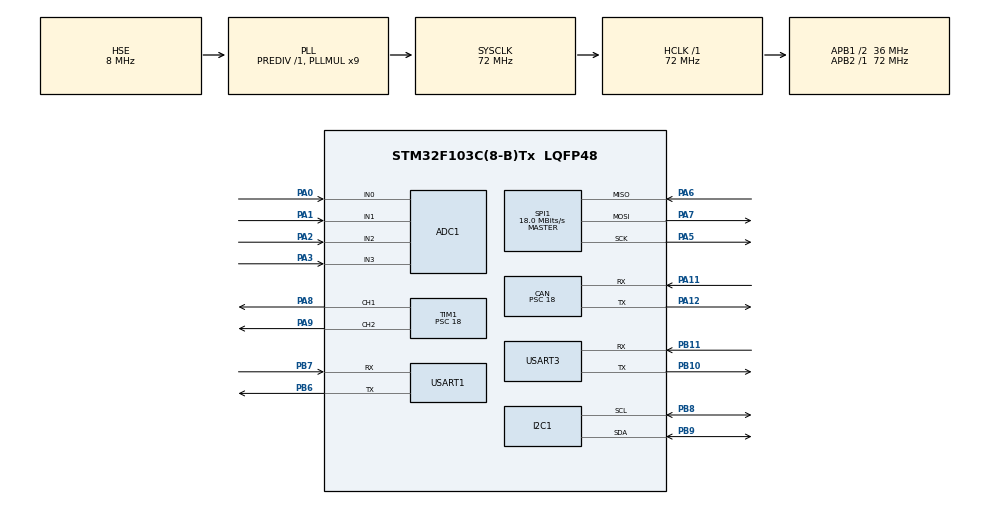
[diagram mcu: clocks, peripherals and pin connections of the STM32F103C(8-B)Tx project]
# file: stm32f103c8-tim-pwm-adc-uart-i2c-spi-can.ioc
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ADC1.Channel-0\#ChannelRegularConversion=ADC_CHANNEL_0
ADC1.Channel-1\#ChannelRegularConversion=ADC_CHANNEL_1
ADC1.Channel-2\#ChannelRegularConversion=ADC_CHANNEL_2
ADC1.Channel-3\#ChannelRegularConversion=ADC_CHANNEL_3
ADC1.ContinuousConvMode=ENABLE
ADC1.NbrOfConversion=4
ADC1.NbrOfConversionFlag=1
ADC1.Rank-0\#ChannelRegularConversion=1
ADC1.Rank-1\#ChannelRegularConversion=2
ADC1.Rank-2\#ChannelRegularConversion=3
ADC1.Rank-3\#ChannelRegularConversion=4
ADC1.SamplingTime-0\#ChannelRegularConversion=ADC_SAMPLETIME_28CYCLES_5
ADC1.SamplingTime-1\#ChannelRegularConversion=ADC_SAMPLETIME_28CYCLES_5
ADC1.SamplingTime-2\#ChannelRegularConversion=ADC_SAMPLETIME_28CYCLES_5
ADC1.SamplingTime-3\#ChannelRegularConversion=ADC_SAMPLETIME_28CYCLES_5
ADC1.master=1
CAN.BS1=CAN_BS1_3TQ
CAN.BS2=CAN_BS2_4TQ
CAN.CalculateBaudRate=250000
CAN.CalculateTimeBit=4000.00
CAN.CalculateTimeQuantum=500.0
CAN.Prescaler=18
Dma.ADC1.6.Direction=DMA_PERIPH_TO_MEMORY
Dma.ADC1.6.Instance=DMA1_Channel1
Dma.ADC1.6.MemDataAlignment=DMA_MDATAALIGN_HALFWORD
Dma.ADC1.6.MemInc=DMA_MINC_ENABLE
Dma.ADC1.6.Mode=DMA_CIRCULAR
Dma.ADC1.6.PeriphDataAlignment=DMA_PDATAALIGN_HALFWORD
Dma.ADC1.6.PeriphInc=DMA_PINC_DISABLE
Dma.ADC1.6.Priority=DMA_PRIORITY_HIGH
Dma.I2C1_RX.2.Direction=DMA_PERIPH_TO_MEMORY
Dma.I2C1_RX.2.Instance=DMA1_Channel7
Dma.I2C1_RX.2.MemDataAlignment=DMA_MDATAALIGN_BYTE
Dma.I2C1_RX.2.MemInc=DMA_MINC_ENABLE
Dma.I2C1_RX.2.Mode=DMA_NORMAL
Dma.I2C1_RX.2.PeriphDataAlignment=DMA_PDATAALIGN_BYTE
Dma.I2C1_RX.2.PeriphInc=DMA_PINC_DISABLE
Dma.I2C1_RX.2.Priority=DMA_PRIORITY_HIGH
Dma.I2C1_TX.3.Direction=DMA_MEMORY_TO_PERIPH
Dma.I2C1_TX.3.Instance=DMA1_Channel6
Dma.I2C1_TX.3.MemDataAlignment=DMA_MDATAALIGN_BYTE
Dma.I2C1_TX.3.MemInc=DMA_MINC_ENABLE
Dma.I2C1_TX.3.Mode=DMA_NORMAL
Dma.I2C1_TX.3.PeriphDataAlignment=DMA_PDATAALIGN_BYTE
Dma.I2C1_TX.3.PeriphInc=DMA_PINC_DISABLE
Dma.I2C1_TX.3.Priority=DMA_PRIORITY_HIGH
Dma.Request0=USART1_RX
Dma.Request1=USART1_TX
Dma.Request2=I2C1_RX
Dma.Request3=I2C1_TX
Dma.Request4=SPI1_RX
Dma.Request5=SPI1_TX
Dma.Request6=ADC1
Dma.SPI1_RX.4.Direction=DMA_PERIPH_TO_MEMORY
Dma.SPI1_RX.4.Instance=DMA1_Channel2
Dma.SPI1_RX.4.MemDataAlignment=DMA_MDATAALIGN_BYTE
Dma.SPI1_RX.4.MemInc=DMA_MINC_ENABLE
Dma.SPI1_RX.4.Mode=DMA_NORMAL
Dma.SPI1_RX.4.PeriphDataAlignment=DMA_PDATAALIGN_BYTE
Dma.SPI1_RX.4.PeriphInc=DMA_PINC_DISABLE
Dma.SPI1_RX.4.Priority=DMA_PRIORITY_HIGH
Dma.SPI1_TX.5.Direction=DMA_MEMORY_TO_PERIPH
Dma.SPI1_TX.5.Instance=DMA1_Channel3
Dma.SPI1_TX.5.MemDataAlignment=DMA_MDATAALIGN_BYTE
Dma.SPI1_TX.5.MemInc=DMA_MINC_ENABLE
Dma.SPI1_TX.5.Mode=DMA_NORMAL
Dma.SPI1_TX.5.PeriphDataAlignment=DMA_PDATAALIGN_BYTE
Dma.SPI1_TX.5.PeriphInc=DMA_PINC_DISABLE
Dma.SPI1_TX.5.Priority=DMA_PRIORITY_HIGH
Dma.USART1_RX.0.Direction=DMA_PERIPH_TO_MEMORY
Dma.USART1_RX.0.Instance=DMA1_Channel5
Dma.USART1_RX.0.MemDataAlignment=DMA_MDATAALIGN_BYTE
Dma.USART1_RX.0.MemInc=DMA_MINC_ENABLE
Dma.USART1_RX.0.Mode=DMA_CIRCULAR
Dma.USART1_RX.0.PeriphDataAlignment=DMA_PDATAALIGN_BYTE
Dma.USART1_RX.0.PeriphInc=DMA_PINC_DISABLE
Dma.USART1_RX.0.Priority=DMA_PRIORITY_HIGH
Dma.USART1_TX.1.Direction=DMA_MEMORY_TO_PERIPH
Dma.USART1_TX.1.Instance=DMA1_Channel4
Dma.USART1_TX.1.MemDataAlignment=DMA_MDATAALIGN_BYTE
Dma.USART1_TX.1.MemInc=DMA_MINC_ENABLE
Dma.USART1_TX.1.Mode=DMA_NORMAL
Dma.USART1_TX.1.PeriphDataAlignment=DMA_PDATAALIGN_BYTE
Dma.USART1_TX.1.PeriphInc=DMA_PINC_DISABLE
Dma.USART1_TX.1.Priority=DMA_PRIORITY_HIGH
FREERTOS.Tasks01=defaultTask,24,128,StartDefaultTask,Default,NULL,Dynamic,NULL,NULL
FREERTOS.Timers01=myTimer01,Callback01,osTimerPeriodic,Default,NULL,Dynamic,NULL
I2C1.I2C_Mode=I2C_Fast
IWDG.Prescaler=IWDG_PRESCALER_64
Mcu.Family=STM32F1
Mcu.Name=STM32F103C(8-B)Tx
Mcu.Package=LQFP48
NVIC.ADC1_2_IRQn=true\:5\:0\:false\:false\:true\:true\:true\:true
NVIC.CAN1_SCE_IRQn=true\:5\:0\:false\:false\:true\:true\:true\:true
NVIC.DMA1_Channel1_IRQn=true\:5\:0\:false\:false\:true\:true\:false\:true
NVIC.DMA1_Channel2_IRQn=true\:5\:0\:false\:false\:true\:true\:false\:true
NVIC.DMA1_Channel3_IRQn=true\:5\:0\:false\:false\:true\:true\:false\:true
NVIC.DMA1_Channel4_IRQn=true\:5\:0\:false\:false\:true\:true\:false\:true
NVIC.DMA1_Channel5_IRQn=true\:5\:0\:false\:false\:true\:true\:false\:true
NVIC.DMA1_Channel6_IRQn=true\:5\:0\:false\:false\:true\:true\:false\:true
NVIC.DMA1_Channel7_IRQn=true\:5\:0\:false\:false\:true\:true\:false\:true
NVIC.I2C1_ER_IRQn=true\:5\:0\:false\:false\:true\:true\:true\:true
NVIC.I2C1_EV_IRQn=true\:5\:0\:false\:false\:true\:true\:true\:true
NVIC.PriorityGroup=NVIC_PRIORITYGROUP_4
NVIC.SPI1_IRQn=true\:5\:0\:false\:false\:true\:true\:true\:true
NVIC.TIM1_BRK_IRQn=true\:5\:0\:false\:false\:true\:true\:true\:true
NVIC.TIM1_CC_IRQn=true\:5\:0\:false\:false\:true\:true\:true\:true
NVIC.TIM1_TRG_COM_IRQn=true\:5\:0\:false\:false\:true\:true\:true\:true
NVIC.TIM1_UP_IRQn=true\:5\:0\:false\:false\:true\:true\:true\:true
NVIC.TIM4_IRQn=true\:0\:0\:false\:false\:true\:false\:false\:true
NVIC.TimeBase=TIM4_IRQn
NVIC.TimeBaseIP=TIM4
NVIC.USART1_IRQn=true\:5\:0\:false\:false\:true\:true\:true\:true
NVIC.USART3_IRQn=true\:5\:0\:false\:false\:true\:true\:true\:true
NVIC.USB_HP_CAN1_TX_IRQn=true\:5\:0\:false\:false\:true\:true\:true\:true
NVIC.USB_LP_CAN1_RX0_IRQn=true\:5\:0\:false\:false\:true\:true\:true\:true
PA0-WKUP.Signal=ADCx_IN0
PA1.Signal=ADCx_IN1
PA11.Mode=CAN_Activate
PA11.Signal=CAN_RX
PA12.Mode=CAN_Activate
PA12.Signal=CAN_TX
PA13.Mode=Serial_Wire
PA13.Signal=SYS_JTMS-SWDIO
PA14.Mode=Serial_Wire
PA14.Signal=SYS_JTCK-SWCLK
PA2.Signal=ADCx_IN2
PA3.Signal=ADCx_IN3
PA5.Mode=Full_Duplex_Master
PA5.Signal=SPI1_SCK
PA6.Mode=Full_Duplex_Master
PA6.Signal=SPI1_MISO
PA7.Mode=Full_Duplex_Master
PA7.Signal=SPI1_MOSI
PA8.Signal=S_TIM1_CH1
PA9.Signal=S_TIM1_CH2
PB10.Mode=Asynchronous
PB10.Signal=USART3_TX
PB11.Mode=Asynchronous
PB11.Signal=USART3_RX
PB6.Mode=Asynchronous
PB6.Signal=USART1_TX
PB7.Mode=Asynchronous
PB7.Signal=USART1_RX
PB8.Mode=I2C
PB8.Signal=I2C1_SCL
PB9.Mode=I2C
PB9.Signal=I2C1_SDA
PD0-OSC_IN.Mode=HSE-External-Oscillator
PD0-OSC_IN.Signal=RCC_OSC_IN
PD1-OSC_OUT.Mode=HSE-External-Oscillator
PD1-OSC_OUT.Signal=RCC_OSC_OUT
ProjectManager.HeapSize=0x400
ProjectManager.StackSize=0x800
ProjectManager.TargetToolchain=MDK-ARM V5.27
RCC.ADCPresc=RCC_ADCPCLK2_DIV6
RCC.AHBFreq_Value=72000000
RCC.APB1CLKDivider=RCC_HCLK_DIV2
RCC.APB1Freq_Value=36000000
RCC.APB1TimFreq_Value=72000000
RCC.APB2Freq_Value=72000000
RCC.APB2TimFreq_Value=72000000
RCC.HCLKFreq_Value=72000000
RCC.PLLMUL=RCC_PLL_MUL9
RCC.PLLSourceVirtual=RCC_PLLSOURCE_HSE
RCC.SYSCLKFreq_VALUE=72000000
RCC.SYSCLKSource=RCC_SYSCLKSOURCE_PLLCLK
RCC.USBFreq_Value=72000000
SH.ADCx_IN0.0=ADC1_IN0,IN0
SH.ADCx_IN1.0=ADC1_IN1,IN1
SH.ADCx_IN2.0=ADC1_IN2,IN2
SH.ADCx_IN3.0=ADC1_IN3,IN3
SH.S_TIM1_CH1.0=TIM1_CH1,Output Compare1 CH1
SH.S_TIM1_CH2.0=TIM1_CH2,Output Compare2 CH2
SPI1.BaudRatePrescaler=SPI_BAUDRATEPRESCALER_4
SPI1.CalculateBaudRate=18.0 MBits/s
SPI1.Direction=SPI_DIRECTION_2LINES
SPI1.Mode=SPI_MODE_MASTER
SPI1.VirtualType=VM_MASTER
TIM1.AutoReloadPreload=TIM_AUTORELOAD_PRELOAD_ENABLE
TIM1.Channel-Output\ Compare1\ CH1=TIM_CHANNEL_1
TIM1.Channel-Output\ Compare2\ CH2=TIM_CHANNEL_2
TIM1.OC1Preload=ENABLE
TIM1.OC2Preload=ENABLE
TIM1.Period=4000
TIM1.Prescaler=18
TIM1.Pulse-Output\ Compare1\ CH1=2000
TIM1.Pulse-Output\ Compare2\ CH2=1000
USART1.VirtualMode=VM_ASYNC
USART3.VirtualMode=VM_ASYNC
VP_FREERTOS_VS_CMSIS_V2.Mode=CMSIS_V2
VP_IWDG_VS_IWDG.Mode=IWDG_Activate
VP_SYS_VS_tim4.Mode=TIM4
VP_TIM1_VS_ClockSourceINT.Mode=Internal
board=custom

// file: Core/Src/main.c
/* USER CODE BEGIN Header */
/**
  ******************************************************************************
  * @file           : main.c
  * @brief          : Main program body
  ******************************************************************************
  * @attention
  *
  * <h2><center>&copy; Copyright (c) 2021 STMicroelectronics.
  * All rights reserved.</center></h2>
  *
  * This software component is licensed by ST under Ultimate Liberty license
  * SLA0044, the "License"; You may not use this file except in compliance with
  * the License. You may obtain a copy of the License at:
  *                             www.st.com/SLA0044
  *
  ******************************************************************************
  */
/* USER CODE END Header */
#include "main.h"
#include "cmsis_os.h"
#include "adc.h"
#include "can.h"
#include "dma.h"
#include "i2c.h"
#include "iwdg.h"
#include "spi.h"
#include "tim.h"
#include "usart.h"
#include "gpio.h"

/* USER CODE BEGIN Includes */
#include "my_task.h"
/* USER CODE END Includes */

void SystemClock_Config(void);
void MX_FREERTOS_Init(void);

int main(void)
{

  /* MCU Configuration--------------------------------------------------------*/

  /* Reset of all peripherals, Initializes the Flash interface and the Systick. */
  HAL_Init();

  /* Configure the system clock */
  SystemClock_Config();

  /* Initialize all configured peripherals */
  MX_GPIO_Init();
  MX_DMA_Init();
  MX_CAN_Init();
  MX_IWDG_Init();
  MX_TIM1_Init();
  MX_USART1_UART_Init();
  MX_I2C1_Init();
  MX_SPI1_Init();
  MX_ADC1_Init();
  MX_USART3_UART_Init();
  /* USER CODE BEGIN 2 */
    custom_peripherals_init();
  /* USER CODE END 2 */

  /* Init scheduler */
  osKernelInitialize();  /* Call init function for freertos objects (in freertos.c) */
  MX_FREERTOS_Init();
  /* Start scheduler */
  osKernelStart();

  /* We should never get here as control is now taken by the scheduler */
  /* Infinite loop */
  while (1)
  {

  }
}

void SystemClock_Config(void)
{
  RCC_OscInitTypeDef RCC_OscInitStruct = {0};
  RCC_ClkInitTypeDef RCC_ClkInitStruct = {0};
  RCC_PeriphCLKInitTypeDef PeriphClkInit = {0};

  /** Initializes the RCC Oscillators according to the specified parameters
  * in the RCC_OscInitTypeDef structure.
  */
  RCC_OscInitStruct.OscillatorType = RCC_OSCILLATORTYPE_LSI|RCC_OSCILLATORTYPE_HSE;
  RCC_OscInitStruct.HSEState = RCC_HSE_ON;
  RCC_OscInitStruct.HSEPredivValue = RCC_HSE_PREDIV_DIV1;
  RCC_OscInitStruct.HSIState = RCC_HSI_ON;
  RCC_OscInitStruct.LSIState = RCC_LSI_ON;
  RCC_OscInitStruct.PLL.PLLState = RCC_PLL_ON;
  RCC_OscInitStruct.PLL.PLLSource = RCC_PLLSOURCE_HSE;
  RCC_OscInitStruct.PLL.PLLMUL = RCC_PLL_MUL9;
  if (HAL_RCC_OscConfig(&RCC_OscInitStruct) != HAL_OK)
  {
    Error_Handler();
  }
  /** Initializes the CPU, AHB and APB buses clocks
  */
  RCC_ClkInitStruct.ClockType = RCC_CLOCKTYPE_HCLK|RCC_CLOCKTYPE_SYSCLK
                              |RCC_CLOCKTYPE_PCLK1|RCC_CLOCKTYPE_PCLK2;
  RCC_ClkInitStruct.SYSCLKSource = RCC_SYSCLKSOURCE_PLLCLK;
  RCC_ClkInitStruct.AHBCLKDivider = RCC_SYSCLK_DIV1;
  RCC_ClkInitStruct.APB1CLKDivider = RCC_HCLK_DIV2;
  RCC_ClkInitStruct.APB2CLKDivider = RCC_HCLK_DIV1;

  if (HAL_RCC_ClockConfig(&RCC_ClkInitStruct, FLASH_LATENCY_2) != HAL_OK)
  {
    Error_Handler();
  }
  PeriphClkInit.PeriphClockSelection = RCC_PERIPHCLK_ADC;
  PeriphClkInit.AdcClockSelection = RCC_ADCPCLK2_DIV6;
  if (HAL_RCCEx_PeriphCLKConfig(&PeriphClkInit) != HAL_OK)
  {
    Error_Handler();
  }
}

 /**
  * @brief  Period elapsed callback in non blocking mode
  * @note   This function is called  when TIM4 interrupt took place, inside
  * HAL_TIM_IRQHandler(). It makes a direct call to HAL_IncTick() to increment
  * a global variable "uwTick" used as application time base.
  * @param  htim : TIM handle
  * @retval None
  */
void HAL_TIM_PeriodElapsedCallback(TIM_HandleTypeDef *htim)
{
  if (htim->Instance == TIM4) {
    HAL_IncTick();
  }
}

void Error_Handler(void)
{
  __disable_irq();
  while (1)
  {
  }
}

/************************ (C) COPYRIGHT STMicroelectronics *****END OF FILE****/

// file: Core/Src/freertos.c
/* USER CODE BEGIN Header */
/**
  ******************************************************************************
  * File Name          : freertos.c
  * Description        : Code for freertos applications
  ******************************************************************************
  * @attention
  *
  * <h2><center>&copy; Copyright (c) 2021 STMicroelectronics.
  * All rights reserved.</center></h2>
  *
  * This software component is licensed by ST under Ultimate Liberty license
  * SLA0044, the "License"; You may not use this file except in compliance with
  * the License. You may obtain a copy of the License at:
  *                             www.st.com/SLA0044
  *
  ******************************************************************************
  */
/* USER CODE END Header */

#include "FreeRTOS.h"
#include "task.h"
#include "main.h"
#include "cmsis_os.h"

/* USER CODE BEGIN Includes */
#include "my_task.h"
/* USER CODE END Includes */

/* Definitions for defaultTask */
osThreadId_t defaultTaskHandle;
const osThreadAttr_t defaultTask_attributes = {
  .name = "defaultTask",
  .stack_size = 32 * 4,
  .priority = (osPriority_t) osPriorityNormal,
};
/* Definitions for myTask_tty */
osThreadId_t myTask_ttyHandle;
const osThreadAttr_t myTask_tty_attributes = {
  .name = "myTask_tty",
  .stack_size = 128 * 6,
  .priority = (osPriority_t) osPriorityNormal,
};
/* Definitions for myTimer01 */
osTimerId_t myTimer01Handle;
const osTimerAttr_t myTimer01_attributes = {
  .name = "myTimer01"
};

void StartDefaultTask(void *argument);
void StartTask_tty(void *argument);
void Callback01(void *argument);

void MX_FREERTOS_Init(void); /* (MISRA C 2004 rule 8.1) */

void MX_FREERTOS_Init(void) {

  /* Create the timer(s) */
  /* creation of myTimer01 */
  myTimer01Handle = osTimerNew(Callback01, osTimerPeriodic, NULL, &myTimer01_attributes);

  /* Create the thread(s) */
  /* creation of defaultTask */
  defaultTaskHandle = osThreadNew(StartDefaultTask, NULL, &defaultTask_attributes);
  /* creation of defaultTask */
  myTask_ttyHandle = osThreadNew(StartTask_tty, NULL, &myTask_tty_attributes);

}

void StartDefaultTask(void *argument)
{
  /* USER CODE BEGIN StartDefaultTask */
  /* Infinite loop */
    portTickType xLastWakeTime;
    xLastWakeTime = xTaskGetTickCount();
    osTimerStart(myTimer01Handle,1000);     //开启1s定时器
    start_adc_dma(ADC_PORT1);
  for(;;)
  {
      IWDG_Feed();
      vTaskDelayUntil(&xLastWakeTime, pdMS_TO_TICKS(800));     //每800ms喂狗一次
  }
  /* USER CODE END StartDefaultTask */
}

void StartTask_tty(void *argument)
{
  /* USER CODE BEGIN StartTask_tty */
  /* Infinite loop */
    uint8_t index = uart_port2index(UART_PORT1);
  for(;;)
  {
      if(pdTRUE == xSemaphoreTake(myBinarySem01Handle, ( TickType_t ) 0 / portTICK_PERIOD_MS ))
          response_func_cmd((char*)usart_info[index].recv_buf);
      osDelay(1);
  }
  /* USER CODE END StartTask_tty */
}

/* Callback01 function */
void Callback01(void *argument)
{
  /* USER CODE BEGIN Callback01 */
    Unix_timestamp++;
  /* USER CODE END Callback01 */
}

/************************ (C) COPYRIGHT STMicroelectronics *****END OF FILE****/
